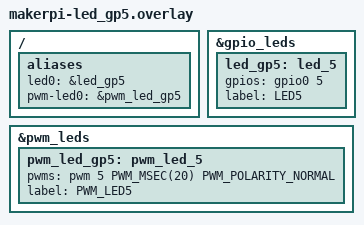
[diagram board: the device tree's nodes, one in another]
/*
 * Copyright (c) 2024 TiaC Systems
 * SPDX-License-Identifier: Apache-2.0
 */

/ {
	aliases {
		led0 = &led_gp5;
		pwm-led0 = &pwm_led_gp5;
	};
};

&gpio_leds {
	led_gp5: led_5 {
		gpios = <&gpio0 5 GPIO_ACTIVE_HIGH>;
		label = "LED5";
	};
};

&pwm_leds {
	pwm_led_gp5: pwm_led_5 {
		pwms = <&pwm 5 PWM_MSEC(20) PWM_POLARITY_NORMAL>;
		label = "PWM_LED5";
	};
};
